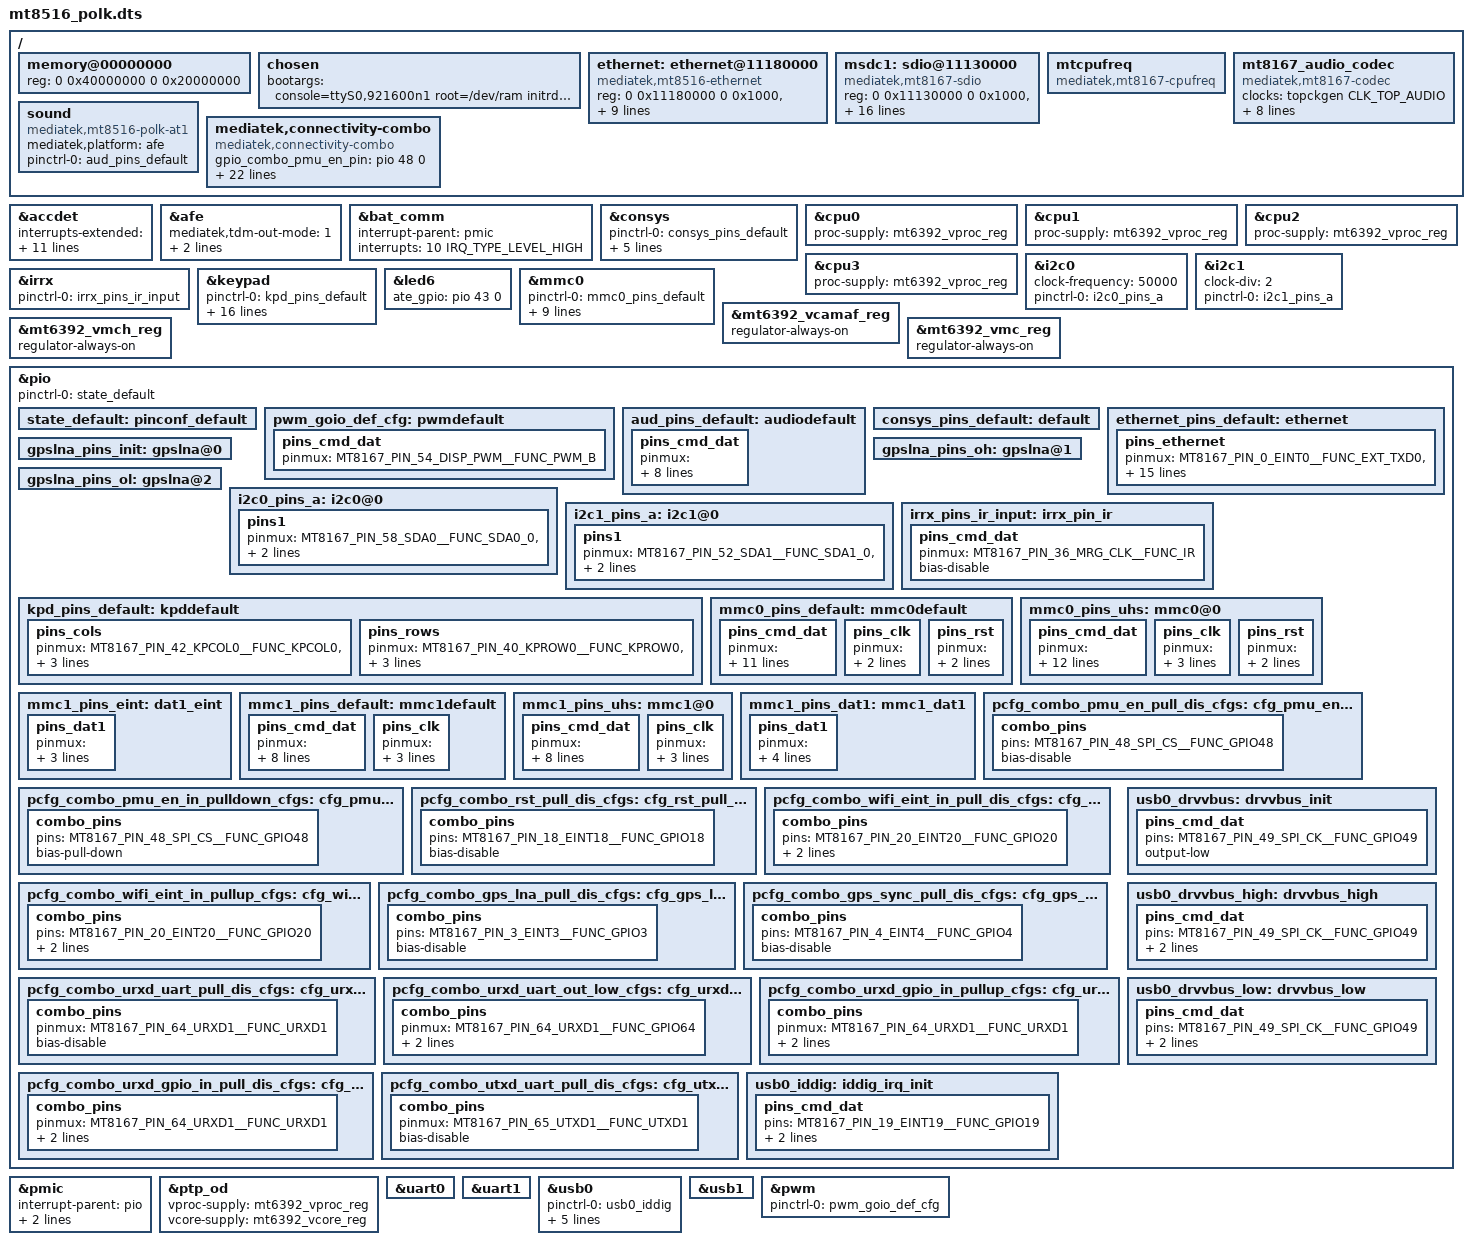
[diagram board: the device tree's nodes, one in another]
/*
 * Copyright (c) 2014-2015 MediaTek Inc.
 *
 * This program is free software; you can redistribute it and/or modify
 * it under the terms of the GNU General Public License version 2 as
 * published by the Free Software Foundation.
 *
 * This program is distributed in the hope that it will be useful,
 * MERCHANTABILITY or FITNESS FOR A PARTICULAR PURPOSE.  See the
 * GNU General Public License for more details.
 */

/dts-v1/;

#include "mt8516.dtsi"
#include "mt6392.dtsi"

/ {
	memory@00000000 {
		device_type = "memory";
		reg = <0 0x40000000 0 0x20000000>;
	};

	/* chosen */
	chosen {
		bootargs = "console=ttyS0,921600n1 root=/dev/ram initrd=0x44000200,0x200000";
	};

	ethernet: ethernet@11180000 {
		compatible = "mediatek,mt8516-ethernet";
		reg = <0 0x11180000 0 0x1000>,
		      <0 0x10003400 0 0x1000>;
		interrupts = <GIC_SPI 111 IRQ_TYPE_LEVEL_LOW>;
		eth-gpios = <&pio 34 0>;
		clocks = <&topckgen CLK_TOP_RG_ETH>,
			 <&topckgen CLK_TOP_66M_ETH>,
			 <&topckgen CLK_TOP_133M_ETH>;
		clock-names = "core", "reg", "trans";
		eth-regulator-supply = <&mt6392_vmch_reg>;
		pinctrl-names = "default";
		pinctrl-0 = <&ethernet_pins_default>;
		mac-address = [00 00 00 00 00 00];
		/*local-mac-address = [00 0C E7 06 00 00];*/
		status = "okay";
	};

	msdc1: sdio@11130000 {
		compatible = "mediatek,mt8167-sdio";
		reg = <0 0x11130000 0 0x1000>,
		      <0 0x10001030 0 0x10>;
		module_reset_bit = <22>;
		interrupts = <GIC_SPI 79 IRQ_TYPE_LEVEL_LOW>;
		clocks = <&topckgen CLK_TOP_MSDC1>,
			 <&topckgen CLK_TOP_AHB_INFRA_SEL>,
			 <&topckgen CLK_TOP_MSDC1_INFRA>;
		clock-names = "source", "hclk", "source_cg";
		status = "disabled";
	};

	mtcpufreq {
		compatible = "mediatek,mt8167-cpufreq";
	};

	mt8167_audio_codec: mt8167_audio_codec {
		compatible = "mediatek,mt8167-codec";
		clocks = <&topckgen CLK_TOP_AUDIO>;
		clock-names = "bus";
		mediatek,afe-regmap = <&afe>;
		mediatek,apmixedsys-regmap = <&apmixedsys>;
		mediatek,pwrap-regmap = <&pwrap>;
		mediatek,speaker-mode = <0>; /* 0(CLASSD) 1(CLASSAB) */
		mediatek,dmic-wire-mode = <1>; /* 0(ONE_WIRE) 1(TWO_WIRE) */
		mediatek,headphone-cap-sel = <1>; /* 0(10UF) 1(22UF) 2(33UF) 3(47UF) */
		mediatek,dmic-rate-mode = <1>; /* 0(1.625M) 1(3.25M) */
		mediatek,micbias0-settle-time-us = <50000>;
	};

	sound: sound {
		compatible = "mediatek,mt8516-polk-at1";
		mediatek,platform = <&afe>;
		pinctrl-names = "default";
		pinctrl-0 = <&aud_pins_default>;
		status = "okay";
	};

	/* Connectivity */
	mediatek,connectivity-combo {
		compatible = "mediatek,connectivity-combo";
		gpio_combo_pmu_en_pin = <&pio 48 0>;	/* GPIO_COMBO_PMU_EN_PIN */
		gpio_combo_rst_pin = <&pio 18 0>;	/* GPIO_COMBO_RST_PIN pin */
		gpio_wifi_eint_pin = <&pio 20 0>;	/* GPIO_WIFI_EINT_PIN */
		gpio_gps_sync_pin = <&pio 4 0>;		/* GPIO_GPS_SYNC_PIN */
		gpio_gps_lna_pin = <&pio 3 0>;		/* GPIO_GPS_LNA_PIN */
		gpio_combo_urxd_pin = <&pio 64 0>;	/* GPIO_COMBO_URXD_PIN */
		gpio_combo_utxd_pin = <&pio 65 0>;	/* GPIO_COMBO_UTXD_PIN */
		pinctrl-names = "gpio_pmu_en_pull_dis",
			"gpio_pmu_en_in_pulldown",
			"gpio_rst_pull_dis",
			"gpio_wifi_eint_in_pull_dis",
			"gpio_wifi_eint_in_pullup",
			"gpio_gps_lna_pull_dis",
			"gpio_gps_sync_pull_dis",
			"gpio_urxd_uart_pull_dis",
			"gpio_urxd_gpio_in_pullup",
			"gpio_urxd_uart_out_low",
			"gpio_urxd_gpio_in_pull_dis",
			"gpio_utxd_uart_pull_dis";
		pinctrl-0 = <&pcfg_combo_pmu_en_pull_dis_cfgs>;
		pinctrl-1 = <&pcfg_combo_pmu_en_in_pulldown_cfgs>;
		pinctrl-2 = <&pcfg_combo_rst_pull_dis_cfgs>;
		pinctrl-3 = <&pcfg_combo_wifi_eint_in_pull_dis_cfgs>;
		pinctrl-4 = <&pcfg_combo_wifi_eint_in_pullup_cfgs>;
		pinctrl-5 = <&pcfg_combo_gps_lna_pull_dis_cfgs>;
		pinctrl-6 = <&pcfg_combo_gps_sync_pull_dis_cfgs>;
		pinctrl-7 = <&pcfg_combo_urxd_uart_pull_dis_cfgs>;
		pinctrl-8 = <&pcfg_combo_urxd_gpio_in_pullup_cfgs>;
		pinctrl-9 = <&pcfg_combo_urxd_uart_out_low_cfgs>;
		pinctrl-10 = <&pcfg_combo_urxd_gpio_in_pull_dis_cfgs>;
		pinctrl-11 = <&pcfg_combo_utxd_uart_pull_dis_cfgs>;
		interrupt-parent = <&pio>;
		interrupts = < 20 IRQ_TYPE_LEVEL_LOW >;	/* WIFI EINT num is 1 active low level-sensitive */
		status = "okay";
	};
};

&accdet {
	interrupts-extended = <&sysirq GIC_SPI 152 IRQ_TYPE_LEVEL_LOW>,
			<&pio 16 IRQ_TYPE_LEVEL_HIGH>;
	eint-debounce = <256000>;
	accdet-gpio = <&pio 16 0>;
	accdet-mic-vol = <7>;
	headset-mode-setting = <0x500 0x500 1 0x1f0 0x800 0x800 0x20>;
	accdet-plugout-debounce = <20>;
	/*1:ACC mode, 2:low cost without in bias, 6:low cost with in bias*/
	accdet-mic-mode = <1>;
	/*0--MD_MAX--UP_MAX--DW_MAX*/
	headset-three-key-threshold = <0 80 220 500>;
	/*0--MD_MAX--VOICE_MAX--UP_MAX--DW_MAX*/
	headset-four-key-threshold = <0 58 121 192 450>;
	status = "okay";
};

&afe {
	/* 0(HDMI) 1(I2S) 2(TDM) */
	mediatek,tdm-out-mode = <1>;
	/* 0(IRQ1) 1(IRQ2) 4(IRQ7) */
	mediatek,awb-irq-mode = <4>;
	mediatek,apply-6db-gain-in-ul-src;
};

&bat_comm {
	interrupt-parent = <&pmic>;
	interrupts = <10 IRQ_TYPE_LEVEL_HIGH>;
};

&consys {
	pinctrl-names = "default", "gps_lna_state_init", "gps_lna_state_oh", "gps_lna_state_ol";
	pinctrl-0 = <&consys_pins_default>;
	pinctrl-1 = <&gpslna_pins_init>;
	pinctrl-2 = <&gpslna_pins_oh>;
	pinctrl-3 = <&gpslna_pins_ol>;
	vcn18-supply = <&mt6392_vcn18_reg>;
	vcn35-supply = <&mt6392_vcn35_reg>;
	status = "okay";
};

&cpu0 {
	proc-supply = <&mt6392_vproc_reg>;
};

&cpu1 {
	proc-supply = <&mt6392_vproc_reg>;
};

&cpu2 {
	proc-supply = <&mt6392_vproc_reg>;
};

&cpu3 {
	proc-supply = <&mt6392_vproc_reg>;
};

&i2c0 {
	clock-frequency = <50000>;
	pinctrl-names = "default";
	pinctrl-0 = <&i2c0_pins_a>;
	status = "okay";
};

&i2c1 {
	clock-div = <2>;
	pinctrl-names = "default";
	pinctrl-0 = <&i2c1_pins_a>;
	status = "okay";
};

&irrx {
	pinctrl-names = "default";
	pinctrl-0 = <&irrx_pins_ir_input>;
	status = "okay";
};

&keypad {
	pinctrl-names = "default";
	pinctrl-0 = <&kpd_pins_default>;
	status = "okay";
	mediatek,kpd-key-debounce = <1024>;
	mediatek,kpd-sw-pwrkey = <0>;
	mediatek,kpd-hw-pwrkey = <0>;
	mediatek,kpd-sw-rstkey  = <0>;
	mediatek,kpd-hw-rstkey = <0>;
	mediatek,kpd-use-extend-type = <0>;
	/*HW Keycode [0~71] -> Linux Keycode*/
	mediatek,kpd-hw-map-num = <72>;
	/*8 rows * 9 columns  */
	mediatek,kpd-hw-init-map = <115 50 0 0 0 0 0 0 0
				30 164 0 0 0 0 0 0 0
				0 0 0 0 0 0 0 0 0
				0 0 0 0 0 0 0 0 0
				0 0 0 0 0 0 0 0 0
				0 0 0 0 0 0 0 0 0
				0 0 0 0 0 0 0 0 0
				0 0 0 0 0 0 0 0 0>;
	mediatek,kpd-pwrkey-eint-gpio = <0>;
	mediatek,kpd-pwkey-gpio-din  = <0>;
	mediatek,kpd-hw-dl-key0 = <0>;
	mediatek,kpd-hw-dl-key1 = <17>;
	mediatek,kpd-hw-dl-key2 = <8>;
	mediatek,kpd-hw-recovery-key = <17>;
	mediatek,kpd-hw-factory-key  = <0>;
};

&led6 {
	ate_gpio = <&pio 43 0>;
};

&mmc0 {
	pinctrl-names = "default", "state_uhs";
	pinctrl-0 = <&mmc0_pins_default>;
	pinctrl-1 = <&mmc0_pins_uhs>;
	status = "okay";
	bus-width = <8>;
	max-frequency = <200000000>;
	cap-mmc-highspeed;
	mmc-hs200-1_8v;
	cap-mmc-hw-reset;
	vmmc-supply = <&mt6392_vemc3v3_reg>;
	vqmmc-supply = <&mt6392_vio18_reg>;
	non-removable;
};

&msdc1 {
	pinctrl-names = "state_eint", "default", "state_uhs", "state_dat1";
	pinctrl-0 = <&mmc1_pins_eint>;
	pinctrl-1 = <&mmc1_pins_default>;
	pinctrl-2 = <&mmc1_pins_uhs>;
	pinctrl-3 = <&mmc1_pins_dat1>;
	eint-gpios = <&pio 107 0>;
	status = "okay";
	bus-width = <4>;
	max-frequency = <200000000>;
	cap-sd-highspeed;
	sd-uhs-sdr50;
	sd-uhs-sdr104;
};

&mt6392_vcamaf_reg {
	regulator-always-on;
};

&mt6392_vmch_reg {
	regulator-always-on;
};

&mt6392_vmc_reg {
	regulator-always-on;
};

&pio {
	pinctrl-names = "default";
	pinctrl-0 = <&state_default>;

	state_default:pinconf_default {
	};


pwm_goio_def_cfg: pwmdefault {
		pins_cmd_dat {
			pinmux = <MT8167_PIN_54_DISP_PWM__FUNC_PWM_B>;
			};
};


	aud_pins_default: audiodefault {
		pins_cmd_dat {
			pinmux = <MT8167_PIN_71_MSDC2_DAT1__FUNC_I2S_8CH_DO1>,
				 <MT8167_PIN_72_MSDC2_DAT2__FUNC_I2S_8CH_LRCK>,
				 <MT8167_PIN_73_MSDC2_DAT3__FUNC_I2S_8CH_BCK>,
				 <MT8167_PIN_55_I2S_DATA_IN__FUNC_I2S0_DI>,
				 <MT8167_PIN_56_I2S_LRCK__FUNC_I2S0_LRCK>,
				 <MT8167_PIN_57_I2S_BCK__FUNC_I2S0_BCK>,
				 <MT8167_PIN_66_LCM_RST__FUNC_GPIO66>;
			drive-strength = <MTK_DRIVE_4mA>;
		};
	};

	/* CONSYS GPIO Settings - Start */
	consys_pins_default: default {

	};
	/* CONSYS GPIO Settings - End */

	ethernet_pins_default: ethernet {
		pins_ethernet {
			pinmux = <MT8167_PIN_0_EINT0__FUNC_EXT_TXD0>,
				 <MT8167_PIN_1_EINT1__FUNC_EXT_TXD1>,
				 <MT8167_PIN_2_EINT2__FUNC_EXT_TXD2>,
				 <MT8167_PIN_3_EINT3__FUNC_EXT_TXD3>,
				 <MT8167_PIN_4_EINT4__FUNC_EXT_TXC>,
				 <MT8167_PIN_5_EINT5__FUNC_EXT_RXER>,
				 <MT8167_PIN_6_EINT6__FUNC_EXT_RXC>,
				 <MT8167_PIN_7_EINT7__FUNC_EXT_RXDV>,
				 <MT8167_PIN_8_EINT8__FUNC_EXT_RXD0>,
				 <MT8167_PIN_9_EINT9__FUNC_EXT_RXD1>,
				 <MT8167_PIN_10_EINT10__FUNC_EXT_RXD2>,
				 <MT8167_PIN_11_EINT11__FUNC_EXT_RXD3>,
				 <MT8167_PIN_12_EINT12__FUNC_EXT_TXEN>,
				 <MT8167_PIN_37_MRG_SYNC__FUNC_EXT_COL>,
				 <MT8167_PIN_38_MRG_DI__FUNC_EXT_MDIO>,
				 <MT8167_PIN_39_MRG_DO__FUNC_EXT_MDC>;
		};
	};

	/* CONSYS GPIO Settings - Start */
	gpslna_pins_init: gpslna@0 {
	};

	gpslna_pins_oh: gpslna@1 {
	};

	gpslna_pins_ol: gpslna@2 {
	};
	/* CONSYS GPIO Settings - End */

	i2c0_pins_a: i2c0@0 {
		pins1 {
			pinmux = <MT8167_PIN_58_SDA0__FUNC_SDA0_0>,
				 <MT8167_PIN_59_SCL0__FUNC_SCL0_0>;
			bias-disable;
		};
	};

	i2c1_pins_a: i2c1@0 {
		pins1 {
			pinmux = <MT8167_PIN_52_SDA1__FUNC_SDA1_0>,
				 <MT8167_PIN_53_SCL1__FUNC_SCL1_0>;
			bias-disable;
		};
	};

	irrx_pins_ir_input: irrx_pin_ir {
		pins_cmd_dat {
			pinmux = <MT8167_PIN_36_MRG_CLK__FUNC_IR>;
			bias-disable;
		};
	};

	kpd_pins_default: kpddefault {
		pins_cols {
			pinmux = <MT8167_PIN_42_KPCOL0__FUNC_KPCOL0>,
				 <MT8167_PIN_43_KPCOL1__FUNC_KPCOL1>;
			input-enable;
			bias-pull-up = <MTK_PUPD_SET_R1R0_01>;
		};

		pins_rows {
			pinmux = <MT8167_PIN_40_KPROW0__FUNC_KPROW0>,
				 <MT8167_PIN_41_KPROW1__FUNC_KPROW1>;
			output-low;
			bias-disable;
		};
	};

	mmc0_pins_default: mmc0default {
		pins_cmd_dat {
			pinmux = <MT8167_PIN_120_MSDC0_DAT0__FUNC_MSDC0_DAT0>,
				<MT8167_PIN_119_MSDC0_DAT1__FUNC_MSDC0_DAT1>,
				<MT8167_PIN_118_MSDC0_DAT2__FUNC_MSDC0_DAT2>,
				<MT8167_PIN_117_MSDC0_DAT3__FUNC_MSDC0_DAT3>,
				<MT8167_PIN_113_MSDC0_DAT4__FUNC_MSDC0_DAT4>,
				<MT8167_PIN_112_MSDC0_DAT5__FUNC_MSDC0_DAT5>,
				<MT8167_PIN_111_MSDC0_DAT6__FUNC_MSDC0_DAT6>,
				<MT8167_PIN_110_MSDC0_DAT7__FUNC_MSDC0_DAT7>,
				<MT8167_PIN_115_MSDC0_CMD__FUNC_MSDC0_CMD>;
			input-enable;
			bias-pull-up;
		};

		pins_clk {
			pinmux = <MT8167_PIN_116_MSDC0_CLK__FUNC_MSDC0_CLK>;
			bias-pull-down;
		};

		pins_rst {
			pinmux = <MT8167_PIN_114_MSDC0_RSTB__FUNC_MSDC0_RSTB>;
			bias-pull-up;
		};
	};

	mmc0_pins_uhs: mmc0@0{
		pins_cmd_dat {
			pinmux = <MT8167_PIN_120_MSDC0_DAT0__FUNC_MSDC0_DAT0>,
				<MT8167_PIN_119_MSDC0_DAT1__FUNC_MSDC0_DAT1>,
				<MT8167_PIN_118_MSDC0_DAT2__FUNC_MSDC0_DAT2>,
				<MT8167_PIN_117_MSDC0_DAT3__FUNC_MSDC0_DAT3>,
				<MT8167_PIN_113_MSDC0_DAT4__FUNC_MSDC0_DAT4>,
				<MT8167_PIN_112_MSDC0_DAT5__FUNC_MSDC0_DAT5>,
				<MT8167_PIN_111_MSDC0_DAT6__FUNC_MSDC0_DAT6>,
				<MT8167_PIN_110_MSDC0_DAT7__FUNC_MSDC0_DAT7>,
				<MT8167_PIN_115_MSDC0_CMD__FUNC_MSDC0_CMD>;
			input-enable;
			drive-strength = <MTK_DRIVE_6mA>;
			bias-pull-up = <MTK_PUPD_SET_R1R0_01>;
		};

		pins_clk {
			pinmux = <MT8167_PIN_116_MSDC0_CLK__FUNC_MSDC0_CLK>;
			drive-strength = <MTK_DRIVE_8mA>;
			bias-pull-down = <MTK_PUPD_SET_R1R0_10>;
		};

		pins_rst {
			pinmux = <MT8167_PIN_114_MSDC0_RSTB__FUNC_MSDC0_RSTB>;
			bias-pull-up;
		};
	};

	mmc1_pins_eint: dat1_eint {
		pins_dat1 {
			pinmux = <MT8167_PIN_107_MSDC1_DAT1__FUNC_GPIO107>;
			input-enable;
			bias-pull-up = <MTK_PUPD_SET_R1R0_01>;
		};
	};

	mmc1_pins_default: mmc1default {
		pins_cmd_dat {
			pinmux = <MT8167_PIN_106_MSDC1_DAT0__FUNC_MSDC1_DAT0>,
				<MT8167_PIN_107_MSDC1_DAT1__FUNC_MSDC1_DAT1>,
				<MT8167_PIN_108_MSDC1_DAT2__FUNC_MSDC1_DAT2>,
				<MT8167_PIN_109_MSDC1_DAT3__FUNC_MSDC1_DAT3>,
				<MT8167_PIN_104_MSDC1_CMD__FUNC_MSDC1_CMD>;
			input-enable;
			drive-strength = <MTK_DRIVE_6mA>;
			bias-pull-up = <MTK_PUPD_SET_R1R0_01>;
		};

		pins_clk {
			pinmux = <MT8167_PIN_105_MSDC1_CLK__FUNC_MSDC1_CLK>;
			drive-strength = <MTK_DRIVE_6mA>;
			bias-pull-down = <MTK_PUPD_SET_R1R0_10>;
		};
	};

	mmc1_pins_uhs: mmc1@0 {
		pins_cmd_dat {
			pinmux = <MT8167_PIN_106_MSDC1_DAT0__FUNC_MSDC1_DAT0>,
				<MT8167_PIN_107_MSDC1_DAT1__FUNC_MSDC1_DAT1>,
				<MT8167_PIN_108_MSDC1_DAT2__FUNC_MSDC1_DAT2>,
				<MT8167_PIN_109_MSDC1_DAT3__FUNC_MSDC1_DAT3>,
				<MT8167_PIN_104_MSDC1_CMD__FUNC_MSDC1_CMD>;
			input-enable;
			drive-strength = <MTK_DRIVE_6mA>;
			bias-pull-up = <MTK_PUPD_SET_R1R0_01>;
		};

		pins_clk {
			pinmux = <MT8167_PIN_105_MSDC1_CLK__FUNC_MSDC1_CLK>;
			drive-strength = <MTK_DRIVE_8mA>;
			bias-pull-down = <MTK_PUPD_SET_R1R0_10>;
		};
	};

	mmc1_pins_dat1: mmc1_dat1 {
		pins_dat1 {
			pinmux = <MT8167_PIN_107_MSDC1_DAT1__FUNC_MSDC1_DAT1>;
			input-enable;
			drive-strength = <MTK_DRIVE_6mA>;
			bias-pull-up = <MTK_PUPD_SET_R1R0_01>;
		};
	};

/* Connectivity GPIO start */
	pcfg_combo_pmu_en_pull_dis_cfgs:cfg_pmu_en_pull_dis {
		combo_pins {
			pins = <MT8167_PIN_48_SPI_CS__FUNC_GPIO48>;
			bias-disable;
		};
	};

	pcfg_combo_pmu_en_in_pulldown_cfgs:cfg_pmu_en_in_pulldown {
		combo_pins {
			pins = <MT8167_PIN_48_SPI_CS__FUNC_GPIO48>;
			bias-pull-down;
		};
	};

	pcfg_combo_rst_pull_dis_cfgs:cfg_rst_pull_dis {
		combo_pins {
			pins = <MT8167_PIN_18_EINT18__FUNC_GPIO18>;
			bias-disable;
		};
	};

	pcfg_combo_wifi_eint_in_pull_dis_cfgs:cfg_wifi_eint_in_pull_dis {
		combo_pins {
			pins = <MT8167_PIN_20_EINT20__FUNC_GPIO20>;
			slew-rate = <0>;
			bias-disable;
		};
	};

	pcfg_combo_wifi_eint_in_pullup_cfgs:cfg_wifi_eint_in_pullup {
		combo_pins {
			pins = <MT8167_PIN_20_EINT20__FUNC_GPIO20>;
			slew-rate = <0>;
			bias-pull-up = <00>;
		};
	};

	pcfg_combo_gps_lna_pull_dis_cfgs:cfg_gps_lna_pull_dis {
		combo_pins {
			pins = <MT8167_PIN_3_EINT3__FUNC_GPIO3>;
			bias-disable;
		};
	};

	pcfg_combo_gps_sync_pull_dis_cfgs:cfg_gps_sync_pull_dis {
		combo_pins {
			pins = <MT8167_PIN_4_EINT4__FUNC_GPIO4>;
			bias-disable;
		};
	};

	pcfg_combo_urxd_uart_pull_dis_cfgs:cfg_urxd_pull_dis {
		combo_pins {
			pinmux = <MT8167_PIN_64_URXD1__FUNC_URXD1>;
			bias-disable;
		};
	};

	pcfg_combo_urxd_uart_out_low_cfgs:cfg_urxd_out_low {
		combo_pins {
			pinmux = <MT8167_PIN_64_URXD1__FUNC_GPIO64>;
			slew-rate = <1>;
			output-low;
		};
	};

	pcfg_combo_urxd_gpio_in_pullup_cfgs:cfg_urxd_in_pullup {
		combo_pins {
			pinmux = <MT8167_PIN_64_URXD1__FUNC_URXD1>;
			input-enable;
			bias-pull-up;
		};
	};

	pcfg_combo_urxd_gpio_in_pull_dis_cfgs:cfg_urxd_in_pull_dis {
		combo_pins {
			pinmux = <MT8167_PIN_64_URXD1__FUNC_URXD1>;
			input-enable;
			bias-disable;
		};
	};

	pcfg_combo_utxd_uart_pull_dis_cfgs:cfg_utxd_pull_dis {
		combo_pins {
			pinmux = <MT8167_PIN_65_UTXD1__FUNC_UTXD1>;
			bias-disable;
		};
	};
/* Connectivity GPIO end */

/* USB GPIO start */
	usb0_drvvbus: drvvbus_init {
		pins_cmd_dat {
			pins = <MT8167_PIN_49_SPI_CK__FUNC_GPIO49>;
			output-low;
		};
	};

	usb0_drvvbus_high: drvvbus_high {
		pins_cmd_dat {
			pins = <MT8167_PIN_49_SPI_CK__FUNC_GPIO49>;
			slew-rate = <1>;
			output-high;
		};
	};

	usb0_drvvbus_low: drvvbus_low {
		pins_cmd_dat {
			pins = <MT8167_PIN_49_SPI_CK__FUNC_GPIO49>;
			slew-rate = <1>;
			output-low;
		};
	};

	usb0_iddig: iddig_irq_init {
		pins_cmd_dat {
			pins = <MT8167_PIN_19_EINT19__FUNC_GPIO19>;
			slew-rate = <0>;
			bias-pull-up = <00>;
		};
	};
/* USB GPIO end */
};

&pmic {
	interrupt-parent = <&pio>;
	interrupts = <28 IRQ_TYPE_LEVEL_HIGH>;
	interrupt-controller;
	#interrupt-cells = <2>;
};

&ptp_od {
	vproc-supply = <&mt6392_vproc_reg>;
	vcore-supply = <&mt6392_vcore_reg>;
};

&uart0 {
	status="okay";
};

&uart1 {
	status="okay";
};

&usb0 {
	pinctrl-names = "iddig_irq_init", "drvvbus_init", "drvvbus_low", "drvvbus_high";
	pinctrl-0 = <&usb0_iddig>;
	pinctrl-1 = <&usb0_drvvbus>;
	pinctrl-2 = <&usb0_drvvbus_low>;
	pinctrl-3 = <&usb0_drvvbus_high>;
	status = "okay";
	drvvbus_gpio = <&pio 49 2>;
	iddig_gpio = <&pio 19 0>;
};

&usb1 {
	status = "okay";
};

&pwm {
	pinctrl-names = "default";
	pinctrl-0 = <&pwm_goio_def_cfg>;
	status = "okay";
};
